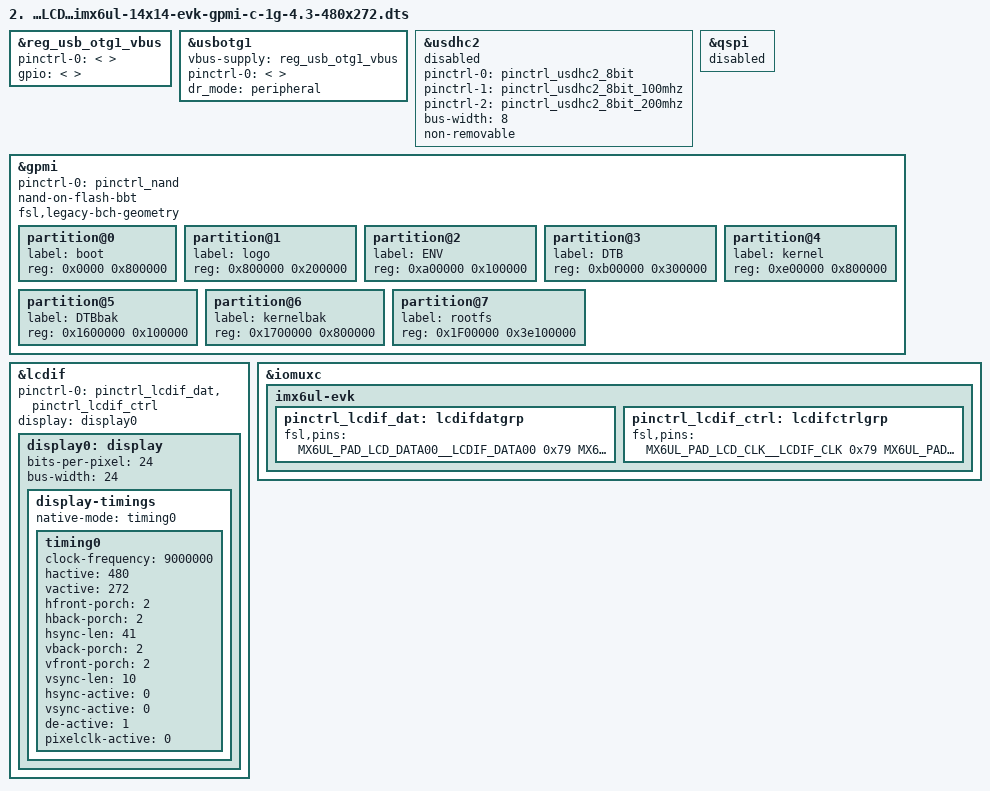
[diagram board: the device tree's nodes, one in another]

/*
 * Copyright (C) 2016 Freescale Semiconductor, Inc.
 *
 * This program is free software; you can redistribute it and/or modify
 * it under the terms of the GNU General Public License version 2 as
 * published by the Free Software Foundation.
 */

#include "imx6ul-14x14-evk.dts"

&reg_usb_otg1_vbus {
        pinctrl-0 = < >;
        gpio = < >;
};
&usbotg1 {
        vbus-supply = <&reg_usb_otg1_vbus>;
        pinctrl-names = "default";
        pinctrl-0 = < >;
        dr_mode = "peripheral";
        status = "okay";
};

&usdhc2 {
    pinctrl-names = "default", "state_100mhz", "state_200mhz";
    pinctrl-0 = <&pinctrl_usdhc2_8bit>;
    pinctrl-1 = <&pinctrl_usdhc2_8bit_100mhz>;
    pinctrl-2 = <&pinctrl_usdhc2_8bit_200mhz>;
    bus-width = <8>;
    non-removable;
    status = "disabled";
};
&qspi {
    status = "disabled";
};
&gpmi {
    pinctrl-names = "default";
        pinctrl-0 = <&pinctrl_nand>;
    nand-on-flash-bbt;
        fsl,legacy-bch-geometry;
    status = "okay";
    partition@0{
        label = "boot";
        reg = <0x0000 0x800000>; /*8M*/
    };
    partition@1{
        label = "logo";
        reg = <0x800000 0x200000>; /*2M*/
    };
    partition@2{
        label = "ENV";
        reg = <0xa00000 0x100000>; /*1M*/
    };
    partition@3{
        label = "DTB";
        reg = <0xb00000 0x300000>; /*3M*/
    };
    partition@4{
        label = "kernel";
        reg = <0xe00000 0x800000>; /*8M*/
    };
    partition@5{
        label = "DTBbak";
        reg = <0x1600000 0x100000>; /*1M*/
    };
    partition@6{
        label = "kernelbak";
        reg = <0x1700000 0x800000>; /*8M*/
    };
    partition@7{
        label = "rootfs";
        reg = <0x1F00000 0x3e100000>;
    };
};
&lcdif {
    pinctrl-names = "default";
    pinctrl-0 = <&pinctrl_lcdif_dat        /* 使用到的IO */
                 &pinctrl_lcdif_ctrl>;
    display = <&display0>;
    status = "okay";

    display0: display {                    /* LCD属性信息 */
        bits-per-pixel = <24>;             /* 1个像素占用几个bit */
        bus-width = <24>;                  /* 总线宽度 */

        display-timings {
            native-mode = <&timing0>;      /* 时序信息 */
            timing0: timing0 {
            clock-frequency = <9000000>;   /* LCD像素时钟，单位HZ */
            hactive = <480>;               /* LCD x轴像素个数 */
            vactive = <272>;               /* LCD y轴像素个数 */
            hfront-porch = <2>;            /* LCD hfp参数 */
            hback-porch = <2>;             /* LCD hbp参数 */
            hsync-len = <41>;              /* LCD hswp参数 */
            vback-porch = <2>;             /* LCD vbp参数 */
            vfront-porch = <2>;            /* LCD vfp参数 */
            vsync-len = <10>;              /* LCD vspw参数 */

            hsync-active = <0>;            /* LCD hsync数据线极性 */
            vsync-active = <0>;            /* LCD vsync数据线极性 */
            de-active = <1>;               /* LCD de数据线极性 */
            pixelclk-active = <0>;         /* LCD clk数据线极性 */
            };
        };
    };
};
&iomuxc {
    imx6ul-evk {
        pinctrl_lcdif_dat: lcdifdatgrp {
            fsl,pins = <
                MX6UL_PAD_LCD_DATA00__LCDIF_DATA00  0x79
                MX6UL_PAD_LCD_DATA01__LCDIF_DATA01  0x79
                MX6UL_PAD_LCD_DATA02__LCDIF_DATA02  0x79
                MX6UL_PAD_LCD_DATA03__LCDIF_DATA03  0x79
                MX6UL_PAD_LCD_DATA04__LCDIF_DATA04  0x79
                MX6UL_PAD_LCD_DATA05__LCDIF_DATA05  0x79
                MX6UL_PAD_LCD_DATA06__LCDIF_DATA06  0x79
                MX6UL_PAD_LCD_DATA07__LCDIF_DATA07  0x79
                MX6UL_PAD_LCD_DATA08__LCDIF_DATA08  0x79
                MX6UL_PAD_LCD_DATA09__LCDIF_DATA09  0x79
                MX6UL_PAD_LCD_DATA10__LCDIF_DATA10  0x79
                MX6UL_PAD_LCD_DATA11__LCDIF_DATA11  0x79
                MX6UL_PAD_LCD_DATA12__LCDIF_DATA12  0x79
                MX6UL_PAD_LCD_DATA13__LCDIF_DATA13  0x79
                MX6UL_PAD_LCD_DATA14__LCDIF_DATA14  0x79
                MX6UL_PAD_LCD_DATA15__LCDIF_DATA15  0x79
                MX6UL_PAD_LCD_DATA16__LCDIF_DATA16  0x79
                MX6UL_PAD_LCD_DATA17__LCDIF_DATA17  0x79
                MX6UL_PAD_LCD_DATA18__LCDIF_DATA18  0x79
                MX6UL_PAD_LCD_DATA19__LCDIF_DATA19  0x79
                MX6UL_PAD_LCD_DATA20__LCDIF_DATA20  0x79
                MX6UL_PAD_LCD_DATA21__LCDIF_DATA21  0x79
                MX6UL_PAD_LCD_DATA22__LCDIF_DATA22  0x79
                MX6UL_PAD_LCD_DATA23__LCDIF_DATA23  0x79
            >;
        };

        pinctrl_lcdif_ctrl: lcdifctrlgrp {
            fsl,pins = <
                MX6UL_PAD_LCD_CLK__LCDIF_CLK        0x79
                MX6UL_PAD_LCD_ENABLE__LCDIF_ENABLE  0x79
                MX6UL_PAD_LCD_HSYNC__LCDIF_HSYNC    0x79  
                MX6UL_PAD_LCD_VSYNC__LCDIF_VSYNC    0x79
                /* used for lcd reset */
    /*          MX6UL_PAD_SNVS_TAMPER9__GPIO5_IO09  0x79  */
            >;
        };  
    };  
};
